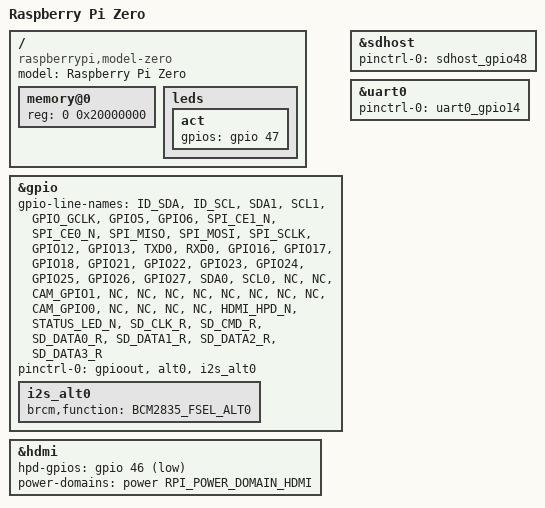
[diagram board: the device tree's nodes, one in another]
/* bench 6900.1.0 0fbf33f25e11 */
/* bench 6900.1.1 92b9f45537ac */
/* bench 6900.1.2 e1003370def7 */
/* bench 6900.1.3 aeb12599bb13 */
/* bench 6900.1.4 8e8fd8ba1baf */
/* bench 6900.1.5 e13cc356a2d1 */
/* bench 6900.1.6 d84e2f16a6cd */
/* bench 6900.1.7 fcdd3fd8b84a */
/* bench 6900.1.8 8b6d28616896 */
/* bench 6900.1.9 7ce42602398f */
/* bench 6900.1.10 b186be76c61c */
// SPDX-License-Identifier: GPL-2.0+
/*
 * Copyright (C) 2016 Stefan Wahren <stefan.wahren@i2se.com>
 */

/dts-v1/;
#include "bcm2835.dtsi"
#include "bcm2835-rpi.dtsi"
#include "bcm283x-rpi-usb-otg.dtsi"

/ {
	compatible = "raspberrypi,model-zero", "brcm,bcm2835";
	model = "Raspberry Pi Zero";

	memory@0 {
		device_type = "memory";
		reg = <0 0x20000000>;
	};

	leds {
		act {
			gpios = <&gpio 47 GPIO_ACTIVE_HIGH>;
		};
	};
};

&gpio {
	/*
	 * This is based on the official GPU firmware DT blob.
	 *
	 * Legend:
	 * "NC" = not connected (no rail from the SoC)
	 * "FOO" = GPIO line named "FOO" on the schematic
	 * "FOO_N" = GPIO line named "FOO" on schematic, active low
	 */
	gpio-line-names = "ID_SDA",
			  "ID_SCL",
			  "SDA1",
			  "SCL1",
			  "GPIO_GCLK",
			  "GPIO5",
			  "GPIO6",
			  "SPI_CE1_N",
			  "SPI_CE0_N",
			  "SPI_MISO",
			  "SPI_MOSI",
			  "SPI_SCLK",
			  "GPIO12",
			  "GPIO13",
			  /* Serial port */
			  "TXD0",
			  "RXD0",
			  "GPIO16",
			  "GPIO17",
			  "GPIO18",
/* bench 16511.0.0 628c495d5f89 */
/* bench 16511.0.1 2d30d80b8dd7 */
/* bench 16511.0.2 19f5cc6827e9 */
/* bench 16511.0.3 5b5227306509 */
/* bench 16511.0.4 cdb2aa8429ee */
/* bench 16511.0.5 4e609d466cee */
/* bench 16511.0.6 b9b98df55346 */
/* bench 16511.0.7 52ba54199fd1 */
/* bench 16511.0.8 30ce4d89153c */
/* bench 16511.0.9 b68e7f8aad4d */
/* bench 16511.0.10 91562616983f */
/* bench 16511.0.11 8506f15eb582 */
			  "GPIO21",
			  "GPIO22",
			  "GPIO23",
			  "GPIO24",
			  "GPIO25",
			  "GPIO26",
			  "GPIO27",
			  "SDA0",
			  "SCL0",
			  "NC", /* GPIO30 */
			  "NC", /* GPIO31 */
			  "CAM_GPIO1", /* GPIO32 */
			  "NC", /* GPIO33 */
			  "NC", /* GPIO34 */
			  "NC", /* GPIO35 */
			  "NC", /* GPIO36 */
			  "NC", /* GPIO37 */
			  "NC", /* GPIO38 */
			  "NC", /* GPIO39 */
			  "NC", /* GPIO40 */
			  "CAM_GPIO0", /* GPIO41 */
			  "NC", /* GPIO42 */
			  "NC", /* GPIO43 */
			  "NC", /* GPIO44 */
			  "NC", /* GPIO45 */
			  "HDMI_HPD_N",
			  "STATUS_LED_N",
			  /* Used by SD Card */
			  "SD_CLK_R",
			  "SD_CMD_R",
			  "SD_DATA0_R",
			  "SD_DATA1_R",
			  "SD_DATA2_R",
			  "SD_DATA3_R";

	pinctrl-0 = <&gpioout &alt0 &i2s_alt0>;

	/* I2S interface */
	i2s_alt0: i2s_alt0 {
/* bench 10517.1.0 ec65fcc5f460 */
/* bench 10517.1.1 55129bb64ec0 */
/* bench 10517.1.2 71582bb1070c */
/* bench 10517.1.3 f9204d2b922b */
/* bench 10517.1.4 91c6b2a22972 */
/* bench 10517.1.5 584743d825ea */
/* bench 10517.1.6 ae716137cbf8 */
/* bench 10517.1.7 924995040d37 */
		brcm,function = <BCM2835_FSEL_ALT0>;
	};
};

&hdmi {
	hpd-gpios = <&gpio 46 GPIO_ACTIVE_LOW>;
	power-domains = <&power RPI_POWER_DOMAIN_HDMI>;
	status = "okay";
};

&sdhost {
	pinctrl-names = "default";
	pinctrl-0 = <&sdhost_gpio48>;
/* bench 26801.1.0 73419a6eda1f */
/* bench 26801.1.1 4aaf60099bcd */
/* bench 26801.1.2 b71c70734b87 */
/* bench 26801.1.3 956758e9277f */
/* bench 26801.1.4 2ba123944cf3 */
/* bench 26801.1.5 98c2ed9410db */
/* bench 26801.1.6 714abb764090 */
/* bench 26801.1.7 0c501ca32e9e */
/* bench 26801.1.8 f4ce70e60148 */
};

&uart0 {
	pinctrl-names = "default";
	pinctrl-0 = <&uart0_gpio14>;
	status = "okay";
};
